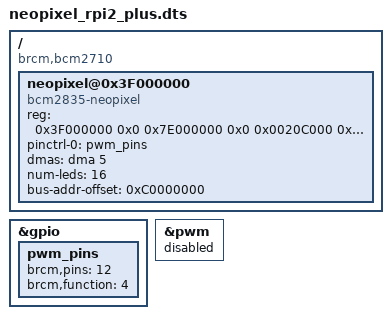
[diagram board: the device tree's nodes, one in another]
/dts-v1/;
/plugin/;

/ {
    compatible = "brcm,bcm2710","brcm,bcm2837";

    fragment@0 {
        target = <&gpio>;
        __overlay__ {
            pwm_pins: pwm_pins {
                brcm,pins = <12>;
                brcm,function = <4>;
            };
        };
    };

    fragment@1 {
      target = <&pwm>;
      __overlay__ {
        status = "disabled";
      };
    };

    fragment@2 {
      target-path = "/";
      __overlay__ {

        #address-cells = <0x1>;
        #size-cells = <0x1>;
        neopixel@0x3F000000 {
          compatible = "bcm2835-neopixel";

          #address-cells = <0x1>;
          #size-cells = <0x1>;

	        reg =  <0x3F000000 0x0     /*0: I/O PHYSICAL ADDRESS*/
                 0x7E000000 0x0      /*1: I/O BUS ADDRESS*/
                 0x0020C000 0x100    /*2: PWM BASE ADDRESS OFFSSET*/
                 0x001010a0 0x08>;   /*3: PWMCTL BASE ADDRESS OFFSSET*/

          reg-names = "neopixel-phys-base","neopixel-bus-base","neopixel-pwm","neopixel-pwmctl-cm";

          pinctrl-0 = <&pwm_pins>;
          pinctrl-names = "default";

          dmas = <&dma 5>;
          dma-names = "neopixel-pwm-dma";

          num-leds = <16>;
          bus-addr-offset = <0xC0000000>;
        };
      };
    };
};
